VERSION "DNNBNNNYNNNNNNNNNNNNNNNNNNYYYNNNNNNNNNNNNN/4/%%%/4/'%**4NNN///"

NS_ :

BS_:

BU_: Navigation TCU Gateway VUM

BO_ 768 msg_tcu: 2 TCU
 SG_ nav_version_update : 15|8@0+ (1,0) [0|255] ""  VUM
 SG_ nav_version_list : 7|8@0+ (1,0) [0|255] ""  VUM

BO_ 256 msg_nav: 1 Navigation
 SG_ nav_update_check : 6|1@0+ (1,0) [0|1] ""  VUM
 SG_ nav_version_check : 7|1@0+ (1,0) [0|1] ""  VUM

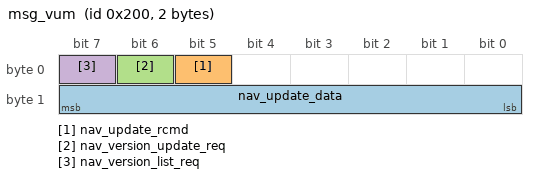
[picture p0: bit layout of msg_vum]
BO_ 512 msg_vum: 2 VUM
 SG_ nav_update_data : 15|8@0+ (1,0) [0|255] ""  Navigation
 SG_ nav_update_rcmd : 5|1@0+ (1,0) [0|1] ""  Navigation
 SG_ nav_version_update_req : 6|1@0+ (1,0) [0|1] ""  TCU
 SG_ nav_version_list_req : 7|1@0+ (1,0) [0|1] ""  TCU

BA_DEF_ BU_  "ILUsed" ENUM  "Yes","No";
BA_DEF_ SG_  "GenSigSendType" ENUM  "Cyclic","OnWrite","OnWriteWithRepetition","OnChange","OnChangeWithRepetition","IfActive","IfActiveWithRepetition";
BA_DEF_ BO_  "GenMsgDelayTime" INT 1 1000;
BA_DEF_ BO_  "GenMsgCycleTime" INT 2 50000;
BA_DEF_ BO_  "GenMsgCycleTimeFast" INT 2 100000;
BA_DEF_ BO_  "GenMsgILSupport" ENUM  "No","Yes";
BA_DEF_ BU_  "NodeLayerModules" STRING ;
BA_DEF_DEF_  "ILUsed" "Yes";
BA_DEF_DEF_  "GenSigSendType" "Cyclic";
BA_DEF_DEF_  "GenMsgDelayTime" 1;
BA_DEF_DEF_  "GenMsgCycleTime" 2;
BA_DEF_DEF_  "GenMsgCycleTimeFast" 100;
BA_DEF_DEF_  "GenMsgILSupport" "Yes";
BA_DEF_DEF_  "NodeLayerModules" "CANoeILNLVector.dll";
BA_ "GenSigSendType" SG_ 768 nav_version_update 3;
BA_ "GenSigSendType" SG_ 768 nav_version_list 3;
BA_ "GenSigSendType" SG_ 256 nav_update_check 3;
BA_ "GenSigSendType" SG_ 256 nav_version_check 3;
BA_ "GenSigSendType" SG_ 512 nav_update_data 3;
BA_ "GenSigSendType" SG_ 512 nav_update_rcmd 3;
BA_ "GenSigSendType" SG_ 512 nav_version_update_req 3;
BA_ "GenSigSendType" SG_ 512 nav_version_list_req 3;
